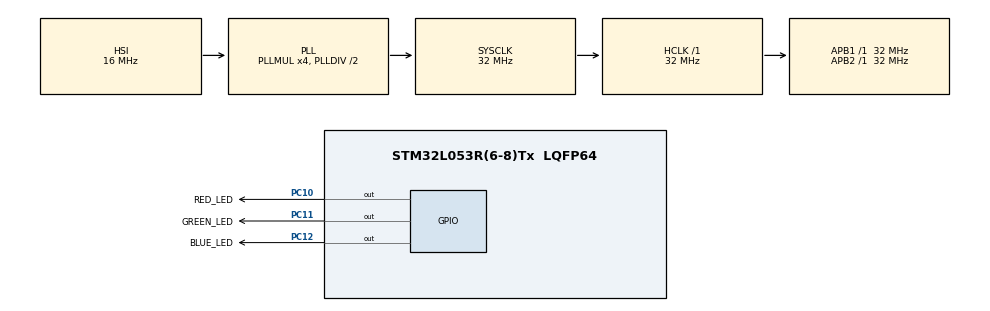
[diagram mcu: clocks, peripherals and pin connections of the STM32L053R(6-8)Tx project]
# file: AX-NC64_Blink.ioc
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Mcu.Family=STM32L0
Mcu.Name=STM32L053R(6-8)Tx
Mcu.Package=LQFP64
PC10.GPIO_Label=RED_LED
PC10.Signal=GPIO_Output
PC11.GPIO_Label=GREEN_LED
PC11.Signal=GPIO_Output
PC12.GPIO_Label=BLUE_LED
PC12.Signal=GPIO_Output
ProjectManager.HeapSize=0x200
ProjectManager.StackSize=0x400
ProjectManager.TargetToolchain=MDK-ARM V5
RCC.AHBFreq_Value=32000000
RCC.APB1Freq_Value=32000000
RCC.APB1TimFreq_Value=32000000
RCC.APB2Freq_Value=32000000
RCC.APB2TimFreq_Value=32000000
RCC.HCLKFreq_Value=32000000
RCC.HSE_VALUE=8000000
RCC.HSI16_VALUE=16000000
RCC.HSI48_VALUE=48000000
RCC.HSI_VALUE=16000000
RCC.LSE_VALUE=32768
RCC.MSI_VALUE=2097000
RCC.PLLMUL=RCC_PLLMUL_4
RCC.SYSCLKFreq_VALUE=32000000
RCC.SYSCLKSource=RCC_SYSCLKSOURCE_PLLCLK
RCC.VCOOutputFreq_Value=64000000
board=custom

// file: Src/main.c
/* USER CODE BEGIN Header */
/**
  ******************************************************************************
  * @file           : main.c
  * @brief          : Main program body
  ******************************************************************************
  * @attention
  *
  * <h2><center>&copy; Copyright (c) 2019 STMicroelectronics.
  * All rights reserved.</center></h2>
  *
  * This software component is licensed by ST under BSD 3-Clause license,
  * the "License"; You may not use this file except in compliance with the
  * License. You may obtain a copy of the License at:
  *                        opensource.org/licenses/BSD-3-Clause
  *
  ******************************************************************************
  */
/* USER CODE END Header */

#include "main.h"

void SystemClock_Config(void);
static void MX_GPIO_Init(void);

int main(void)
{

  /* MCU Configuration--------------------------------------------------------*/

  /* Reset of all peripherals, Initializes the Flash interface and the Systick. */
  HAL_Init();

  /* Configure the system clock */
  SystemClock_Config();

  /* Initialize all configured peripherals */
  MX_GPIO_Init();

  /* Infinite loop */
  /* USER CODE BEGIN WHILE */
  while (1)
  {
		// trun on all led on board
		HAL_GPIO_WritePin(RED_LED_GPIO_Port, RED_LED_Pin, 1);
		HAL_GPIO_WritePin(GREEN_LED_GPIO_Port, GREEN_LED_Pin, 1);
		HAL_GPIO_WritePin(BLUE_LED_GPIO_Port, BLUE_LED_Pin, 1);
		HAL_Delay(500);

		// Trun off all led on board
		HAL_GPIO_WritePin(RED_LED_GPIO_Port, RED_LED_Pin, 0);
		HAL_GPIO_WritePin(GREEN_LED_GPIO_Port, GREEN_LED_Pin, 0);
		HAL_GPIO_WritePin(BLUE_LED_GPIO_Port, BLUE_LED_Pin, 0);
		HAL_Delay(500);
    /* USER CODE END WHILE */

  }
}

void SystemClock_Config(void)
{
  RCC_OscInitTypeDef RCC_OscInitStruct = {0};
  RCC_ClkInitTypeDef RCC_ClkInitStruct = {0};

  /** Configure the main internal regulator output voltage
  */
  __HAL_PWR_VOLTAGESCALING_CONFIG(PWR_REGULATOR_VOLTAGE_SCALE1);
  /** Initializes the CPU, AHB and APB busses clocks
  */
  RCC_OscInitStruct.OscillatorType = RCC_OSCILLATORTYPE_HSI;
  RCC_OscInitStruct.HSIState = RCC_HSI_ON;
  RCC_OscInitStruct.HSICalibrationValue = RCC_HSICALIBRATION_DEFAULT;
  RCC_OscInitStruct.PLL.PLLState = RCC_PLL_ON;
  RCC_OscInitStruct.PLL.PLLSource = RCC_PLLSOURCE_HSI;
  RCC_OscInitStruct.PLL.PLLMUL = RCC_PLLMUL_4;
  RCC_OscInitStruct.PLL.PLLDIV = RCC_PLLDIV_2;
  if (HAL_RCC_OscConfig(&RCC_OscInitStruct) != HAL_OK)
  {
    Error_Handler();
  }
  /** Initializes the CPU, AHB and APB busses clocks
  */
  RCC_ClkInitStruct.ClockType = RCC_CLOCKTYPE_HCLK|RCC_CLOCKTYPE_SYSCLK
                              |RCC_CLOCKTYPE_PCLK1|RCC_CLOCKTYPE_PCLK2;
  RCC_ClkInitStruct.SYSCLKSource = RCC_SYSCLKSOURCE_PLLCLK;
  RCC_ClkInitStruct.AHBCLKDivider = RCC_SYSCLK_DIV1;
  RCC_ClkInitStruct.APB1CLKDivider = RCC_HCLK_DIV1;
  RCC_ClkInitStruct.APB2CLKDivider = RCC_HCLK_DIV1;

  if (HAL_RCC_ClockConfig(&RCC_ClkInitStruct, FLASH_LATENCY_1) != HAL_OK)
  {
    Error_Handler();
  }
}

static void MX_GPIO_Init(void)
{
  GPIO_InitTypeDef GPIO_InitStruct = {0};

  /* GPIO Ports Clock Enable */
  __HAL_RCC_GPIOC_CLK_ENABLE();

  /*Configure GPIO pin Output Level */
  HAL_GPIO_WritePin(GPIOC, RED_LED_Pin|GREEN_LED_Pin|BLUE_LED_Pin, GPIO_PIN_RESET);

  /*Configure GPIO pins : RED_LED_Pin GREEN_LED_Pin BLUE_LED_Pin */
  GPIO_InitStruct.Pin = RED_LED_Pin|GREEN_LED_Pin|BLUE_LED_Pin;
  GPIO_InitStruct.Mode = GPIO_MODE_OUTPUT_PP;
  GPIO_InitStruct.Pull = GPIO_NOPULL;
  GPIO_InitStruct.Speed = GPIO_SPEED_FREQ_LOW;
  HAL_GPIO_Init(GPIOC, &GPIO_InitStruct);

}

void Error_Handler(void)
{
}

/************************ (C) COPYRIGHT STMicroelectronics *****END OF FILE****/
